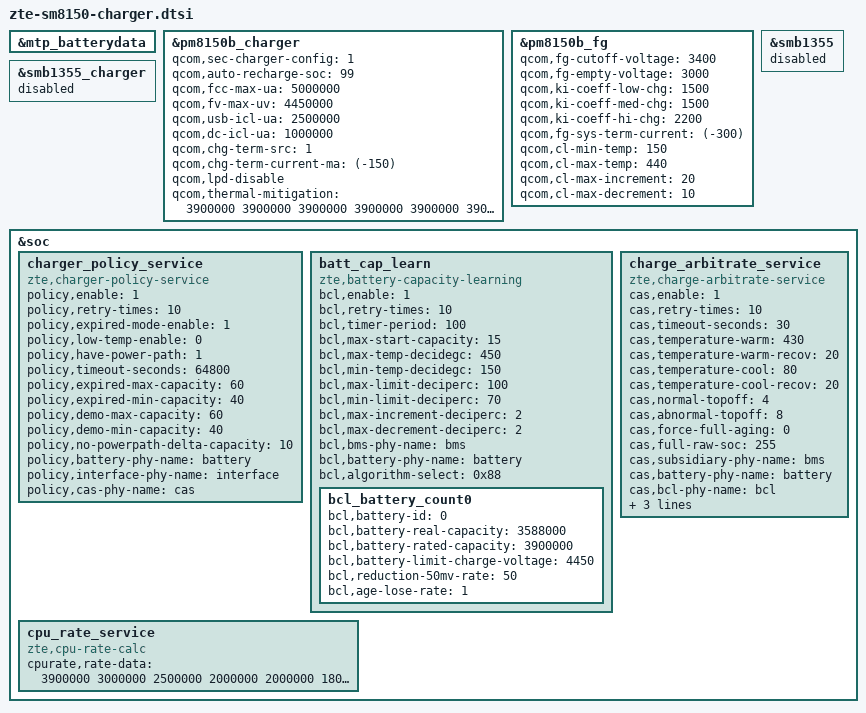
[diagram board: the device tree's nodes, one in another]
&mtp_batterydata {

	/delete-node/ qcom,alium_860_89032_0000_3600mah_averaged_masterslave_sep24th2018;
	#include "3409296_ZTE_cos_4000mAh_averaged_MasterSlave_Oct30th2018_PM8150BGUI10010.dtsi"
};

&pm8150b_charger {
	qcom,sec-charger-config = <1>;
	qcom,auto-recharge-soc = <99>;
	qcom,fcc-max-ua = <5000000>;
	qcom,fv-max-uv = <4450000>;
	qcom,usb-icl-ua = <2500000>;
	qcom,dc-icl-ua = <1000000>;
	qcom,chg-term-src = <1>;
	qcom,chg-term-current-ma = <(-150)>;
	qcom,lpd-disable;
	/* external thermal-mitigation for different case
	usb fcc @ screen off
	usb fcc @ screen on
	dc fcc @ screen off
	dc fcc @ screen on */
	qcom,thermal-mitigation
		= <3900000 3900000 3900000 3900000 3900000 3900000 3000000 2500000 2000000 1000000 500000
		3900000 3000000 3000000 3000000 3000000 2500000 2000000 1500000 1000000 500000 300000
		3000000 2000000 1750000 1500000 1250000 1000000 750000 500000 400000 300000 100000
		300000 300000 300000 300000 300000 300000 300000 300000 100000 100000 100000>;
};

&pm8150b_fg {
	qcom,fg-cutoff-voltage = <3400>;
	qcom,fg-empty-voltage = <3000>;
	qcom,ki-coeff-low-chg = <1500>;
	qcom,ki-coeff-med-chg = <1500>;
	qcom,ki-coeff-hi-chg = <2200>;
	qcom,fg-sys-term-current = <(-300)>;
	qcom,cl-min-temp = <150>;
	qcom,cl-max-temp = <440>;
	qcom,cl-max-increment = <20>;
	qcom,cl-max-decrement = <10>;
};

&smb1355 {
	status = "disabled";
};

&smb1355_charger {
	status = "disabled";
};

&soc {
	charger_policy_service {
		compatible = "zte,charger-policy-service";
		status="okay";
		policy,enable = <1>;
		policy,retry-times = <10>;
		policy,expired-mode-enable = <1>;
		policy,low-temp-enable = <0>;
		policy,have-power-path = <1>;
		policy,timeout-seconds = <64800>;/* 18 hours */
		policy,expired-max-capacity = <60>;
		policy,expired-min-capacity = <40>;
		policy,demo-max-capacity = <60>;
		policy,demo-min-capacity = <40>;
		policy,no-powerpath-delta-capacity = <10>;
		policy,battery-phy-name = "battery";
		policy,interface-phy-name = "interface";
		policy,cas-phy-name = "cas";
	};

	batt_cap_learn {
		compatible = "zte,battery-capacity-learning";
		bcl,enable = <1>;
		bcl,retry-times = <10>;
		bcl,timer-period = <100>;/*ms*/
		bcl,max-start-capacity = <15>;
		bcl,max-temp-decidegc = <450>;
		bcl,min-temp-decidegc = <150>;
		bcl,max-limit-deciperc = <100>;
		bcl,min-limit-deciperc = <70>;
		bcl,max-increment-deciperc = <2>;
		bcl,max-decrement-deciperc = <2>;
		bcl,bms-phy-name = "bms";
		bcl,battery-phy-name = "battery";
		/*bit7: 0: use zte algorithm calc age; 1: use platform algorithm calc age*/
		/*bit4: enable zte algorithm*/
		/*bit3: enable platform algorithm*/
		/*bit0: platform algorithm mode 0: integral mode; 1: delta mode*/
		bcl,algorithm-select = <0x88>;

		bcl_battery_count0 {
			bcl,battery-id = <0>;
			/*"real capacity" = "rated capacity" - "voltage diff" - "topoff diff"*/
			/*TMB TEST REAL CAPACITY 92%*/
			bcl,battery-real-capacity = <3588000>;
			bcl,battery-rated-capacity = <3900000>;
			bcl,battery-limit-charge-voltage = <4450>;
			bcl,reduction-50mv-rate = <50>;/*rate * 10*/
			bcl,age-lose-rate = <1>;/*rate * 10*/
		};
	};

	charge_arbitrate_service {
		compatible = "zte,charge-arbitrate-service";
		cas,enable = <1>;
		cas,retry-times = <10>;
		cas,timeout-seconds = <30>;/*s*/
		cas,temperature-warm = <430>;
		cas,temperature-warm-recov = <20>;
		cas,temperature-cool = <80>;
		cas,temperature-cool-recov = <20>;
		cas,normal-topoff = <4>;
		cas,abnormal-topoff = <8>;
		cas,force-full-aging = <0>;
		cas,full-raw-soc = <255>;
		cas,subsidiary-phy-name = "bms";
		cas,battery-phy-name = "battery";
		cas,bcl-phy-name = "bcl";
		cas,interface-phy-name = "interface";
		/* age, fcv, fcc, rech_soc_1st, rech_soc_2st rech_vol_1st, rech_vol_2st **/
		/* age, fcv, fcc, rech_soc_1st, rech_soc_2st rech_vol_1st, rech_vol_2st **/
		cas,age-data = <100 4450000 3900000 99 97 0 0
				95 4430000 3700000 98 96 0 0
				90 4410000 3500000 97 95 0 0
				85 4390000 3360000 96 94 0 0
				80 4370000 3180000 95 93 0 0
				75 4350000 2900000 94 92 0 0>;
	};

	cpu_rate_service {
		compatible = "zte,cpu-rate-calc";
		status = "okay";
		cpurate,rate-data = <3900000 3000000 2500000 2000000 2000000
							1800000 1500000 1000000 600000 300000 300000>;
	};
};
